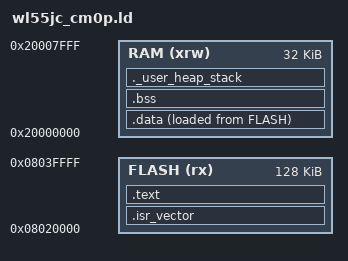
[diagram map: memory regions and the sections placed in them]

MEMORY
{
  FLASH (rx)  : ORIGIN = 0x08020000, LENGTH = 128K
  RAM   (xrw) : ORIGIN = 0x20000000, LENGTH = 32K
}

_estack         = ORIGIN(RAM) + LENGTH(RAM);
_Min_Heap_Size  = 0x200;
_Min_Stack_Size = 0x400;

SECTIONS
{
  .isr_vector :
  {
    . = ALIGN(4);
    KEEP(*(.isr_vector))
    . = ALIGN(4);
  } >FLASH

  .text :
  {
    . = ALIGN(4);
    *(.text)
    *(.text*)
    *(.rodata)
    *(.rodata*)
    . = ALIGN(4);
    _etext = .;
  } >FLASH

  .data :
  {
    . = ALIGN(4);
    _sdata = .;
    *(.data)
    *(.data*)
    . = ALIGN(4);
    _edata = .;
  } >RAM AT>FLASH

  _sidata = LOADADDR(.data);

  .bss :
  {
    . = ALIGN(4);
    _sbss = .;
    *(.bss)
    *(.bss*)
    *(COMMON)
    . = ALIGN(4);
    _ebss = .;
  } >RAM

  ._user_heap_stack :
  {
    . = ALIGN(8);
    PROVIDE(end = .);
    . = . + _Min_Heap_Size;
    . = . + _Min_Stack_Size;
    . = ALIGN(8);
  } >RAM
}
